AUTOSAR XML (schema 4-2-2)
standard types defined: UInt8, UInt16, uint8, uint16
package /SwcCELCmgr_pkg/SwcCELCmgr_swc
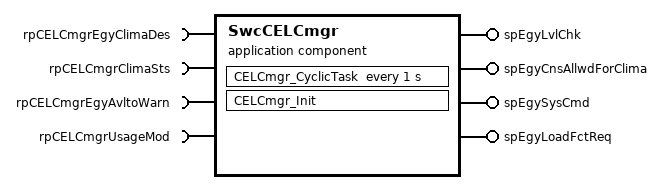
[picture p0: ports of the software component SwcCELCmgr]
  application sw component type SwcCELCmgr
    4 x require port:
      rpCELCmgrEgyClimaDes: nonqueued-receiver-com-spec{data-element=EgyClimaDes, alive-timeout=60, init-value=constant-reference={short-label=DefaultInitValue_UInt16, constant=DefaultInitValue_UInt16}}, required-interface=rpCELCmgrEgyClimaDes
      rpCELCmgrClimaSts: nonqueued-receiver-com-spec{data-element=ClimaSts, alive-timeout=60, init-value=constant-reference={short-label=DefaultInitValue_UInt8, constant=DefaultInitValue_UInt8}}, required-interface=rpCELCmgrClimaSts
      rpCELCmgrEgyAvltoWarn: nonqueued-receiver-com-spec{data-element=EgyAvltoWarn, alive-timeout=60, init-value=constant-reference={short-label=DefaultInitValue_UInt16, constant=DefaultInitValue_UInt16}}, required-interface=rpCELCmgrEgyAvltoWarn
      rpCELCmgrUsageMod: nonqueued-receiver-com-spec{data-element=UsageMod, alive-timeout=60, init-value=constant-reference={short-label=DefaultInitValue_UInt8, constant=DefaultInitValue_UInt8}}, required-interface=rpCELCmgrUsageMod
    4 x provide port:
      spEgyLvlChk: nonqueued-sender-com-spec{data-element=EgyLvlChk, init-value=constant-reference={short-label=DefaultInitValue_UInt8, constant=DefaultInitValue_UInt8}}, provided-interface=spEgyLvlChk
      spEgyCnsAllwdForClima: nonqueued-sender-com-spec{data-element=EgyCnsAllwdForClima, init-value=constant-reference={short-label=DefaultInitValue_UInt16, constant=DefaultInitValue_UInt16}}, provided-interface=spEgyCnsAllwdForClima
      spEgySysCmd: nonqueued-sender-com-spec{data-element=EgySysCmd, init-value=constant-reference={short-label=DefaultInitValue_UInt8, constant=DefaultInitValue_UInt8}}, provided-interface=spEgySysCmd
      spEgyLoadFctReq: nonqueued-sender-com-spec{data-element=EgyLoadFctReq, init-value=constant-reference={short-label=DefaultInitValue_UInt8, constant=DefaultInitValue_UInt8}}, provided-interface=spEgyLoadFctReq
    behavior SwcCELCmgr: handle-termination-and-restart=NO-SUPPORT
      constant-memorys:
        4 x parameter data prototype, all with category=VALUE, sw-calibration-access=READ-WRITE:
          CELCmgr_TEgyChkTime_5min: type=UInt16, init-value=constant-reference={short-label=CELCmgr_TEgyChkTime_5min, constant=CELCmgr_TEgyChkTime_5min}
          CELCmgr_EgyClimaAllwdFac: type=UInt8, init-value=constant-reference={short-label=CELCmgr_EgyClimaAllwdFac, constant=CELCmgr_EgyClimaAllwdFac}
          CELCmgr_EgyCnsAllwdForClimaMax: type=UInt8, init-value=constant-reference={short-label=CELCmgr_EgyCnsAllwdForClimaMax, constant=CELCmgr_EgyCnsAllwdForClimaMax}
          CELCmgr_TclimaMax: type=UInt8, init-value=constant-reference={short-label=CELCmgr_TclimaMax, constant=CELCmgr_TclimaMax}
      timing event Event_Runnable_Step: start-on-event=CELCmgr_CyclicTask, period=1
      init event Event: start-on-event=CELCmgr_Init
      runnable CELCmgr_Init
      runnable CELCmgr_CyclicTask
        data-read-access:
          4 x access:
            IN_rpCELCmgrClimaSts_ClimaSts: accessed-variable=rpCELCmgrClimaSts.ClimaSts
            IN_rpCELCmgrEgyAvltoWarn_EgyAvltoWarn: accessed-variable=rpCELCmgrEgyAvltoWarn.EgyAvltoWarn
            IN_rpCELCmgrEgyClimaDes_EgyClimaDes: accessed-variable=rpCELCmgrEgyClimaDes.EgyClimaDes
            IN_rpCELCmgrUsageMod_UsageMod: accessed-variable=rpCELCmgrUsageMod.UsageMod
        data-write-access:
          4 x access:
            OUT_spEgyLvlChk_EgyLvlChk: accessed-variable=spEgyLvlChk.EgyLvlChk
            OUT_spEgyCnsAllwdForClima_EgyCnsAllwdForClima: accessed-variable=spEgyCnsAllwdForClima.EgyCnsAllwdForClima
            OUT_spEgySysCmd_EgySysCmd: accessed-variable=spEgySysCmd.EgySysCmd
            OUT_spEgyLoadFctReq_EgyLoadFctReq: accessed-variable=spEgyLoadFctReq.EgyLoadFctReq
  8 x sender receiver interface:
    rpCELCmgrEgyClimaDes
      data EgyClimaDes: category=VALUE, type=UInt16
    rpCELCmgrClimaSts
      data ClimaSts: category=VALUE, type=UInt8
    rpCELCmgrEgyAvltoWarn
      data EgyAvltoWarn: category=VALUE, type=UInt16
    rpCELCmgrUsageMod
      data UsageMod: category=VALUE, type=UInt8
    spEgyLvlChk
      data EgyLvlChk: category=VALUE, type=UInt8
    spEgyCnsAllwdForClima
      data EgyCnsAllwdForClima: category=VALUE, type=UInt16
    spEgySysCmd
      data EgySysCmd: category=VALUE, type=UInt8
    spEgyLoadFctReq
      data EgyLoadFctReq: category=VALUE, type=UInt8
package /SwcCELCmgr_pkg/SwcCELCmgr_swc/Ground
  7 x constant specification:
    CELCmgr_EgyClimaAllwdFac: value-spec=CELCmgr_EgyClimaAllwdFac:80
    CELCmgr_Tclima: value-spec=CELCmgr_Tclima:60
    CELCmgr_TEgyChkTime_5min: value-spec=CELCmgr_TEgyChkTime_5min:30000
    CELCmgr_TclimaMax: value-spec=CELCmgr_TclimaMax:12
    DefaultInitValue_UInt8: value-spec=0
    DefaultInitValue_UInt16: value-spec=0
    CELCmgr_EgyCnsAllwdForClimaMax: value-spec=CELCmgr_EgyCnsAllwdForClimaMax:127
package /SwcCELCmgr_pkg/SwcCELCmgr_imp
  swc implementation SwcCELCmgr: programming-language=C, sw-version=1.232.1, used-code-generator=Embedded Coder 6.13 (R2017b) 24-Jul-2017, vendor-id=0, behavior=SwcCELCmgr
    code-descriptors:
      code Code
        artifact-descriptors:
          short-label=SwcCELCmgr_c, category=SWSRC
          short-label=ChartInfoStruct_h, category=SWHDR
          short-label=DebuggerRuntimeInterface_h, category=SWHDR
          short-label=MatlabDataArray_hpp, category=SWHDR
          short-label=MatlabEngine_hpp, category=SWHDR
          short-label=MessageServiceLayer_h, category=SWHDR
          short-label=SwcCELCmgr_h, category=SWHDR
          short-label=SwcCELCmgr_private_h, category=SWHDR
          short-label=SwcCELCmgr_types_h, category=SWHDR
          short-label=bio_sig_h, category=SWHDR
          short-label=blas_h, category=SWHDR
          short-label=blascompat32_h, category=SWHDR
          short-label=cg_matrx_h, category=SWHDR
          short-label=cg_sfun_h, category=SWHDR
          short-label=cgxert_h, category=SWHDR
          short-label=covrt_h, category=SWHDR
          short-label=cvstCG_ComputeMetric_h, category=SWHDR
          short-label=cvstCG_foregroundDetector_h, category=SWHDR
          short-label=cvstCG_ocrutils_h, category=SWHDR
          short-label=dt_info_h, category=SWHDR
          short-label=emlrt_h, category=SWHDR
          short-label=engine_h, category=SWHDR
          short-label=ext_share_h, category=SWHDR
          short-label=ext_svr_h, category=SWHDR
          short-label=ext_svr_transport_h, category=SWHDR
          short-label=ext_test_h, category=SWHDR
          short-label=ext_types_h, category=SWHDR
          short-label=ext_work_h, category=SWHDR
          short-label=fintrf_h, category=SWHDR
          short-label=fixedpoint_h, category=SWHDR
          short-label=fixpoint_spec_h, category=SWHDR
          short-label=io64_h, category=SWHDR
          short-label=lapack_h, category=SWHDR
          short-label=lapacke_h, category=SWHDR
          short-label=lapacke_config_h, category=SWHDR
          short-label=libmwboxfilter_h, category=SWHDR
          short-label=libmwboxfilter3_h, category=SWHDR
          short-label=libmwbwdistEDT_h, category=SWHDR
          short-label=libmwbwdistEDTFT_h, category=SWHDR
          short-label=libmwbwdistEDTFT_tbb_h, category=SWHDR
          short-label=libmwbwdistEDT_tbb_h, category=SWHDR
          short-label=libmwbwlookup_h, category=SWHDR
          short-label=libmwbwlookup_tbb_h, category=SWHDR
          short-label=libmwbwpackc_h, category=SWHDR
          short-label=libmwbwpackctbb_h, category=SWHDR
          short-label=libmwbwunpackc_h, category=SWHDR
          short-label=libmwbwunpackctbb_h, category=SWHDR
          short-label=libmwcannythresholding_tbb_h, category=SWHDR
          short-label=libmwddist_h, category=SWHDR
          short-label=libmwedgesobelprewitt_tbb_h, category=SWHDR
          short-label=libmwedgethinning_tbb_h, category=SWHDR
          short-label=libmwgetnumcores_h, category=SWHDR
          short-label=libmwgrayto16_h, category=SWHDR
          short-label=libmwgrayto8_h, category=SWHDR
          short-label=libmwgrayxform_h, category=SWHDR
          short-label=libmwgrayxform_tbb_h, category=SWHDR
          short-label=libmwimfilter_h, category=SWHDR
          short-label=libmwimlincomb_h, category=SWHDR
          short-label=libmwimlincomb_tbb_h, category=SWHDR
          short-label=libmwimreconstruct_h, category=SWHDR
          short-label=libmwimregionalmax_h, category=SWHDR
          short-label=libmwint16touint16_h, category=SWHDR
          short-label=libmwint32touint32_h, category=SWHDR
          short-label=libmwint8touint8_h, category=SWHDR
          short-label=libmwintlut_h, category=SWHDR
          short-label=libmwintluttbb_h, category=SWHDR
          short-label=libmwippfilter_h, category=SWHDR
          short-label=libmwippgeotrans_h, category=SWHDR
          short-label=libmwippmedianfilter_h, category=SWHDR
          short-label=libmwippreconstruct_h, category=SWHDR
          short-label=libmwjpegreader_h, category=SWHDR
          short-label=libmwmorphop_binary_h, category=SWHDR
          short-label=libmwmorphop_binary_tbb_h, category=SWHDR
          short-label=libmwmorphop_flat_h, category=SWHDR
          short-label=libmwmorphop_flat_tbb_h, category=SWHDR
          short-label=libmwmorphop_nonflat_h, category=SWHDR
          short-label=libmwmorphop_nonflat_tbb_h, category=SWHDR
          short-label=libmwmorphop_ocv_h, category=SWHDR
          short-label=libmwmorphop_packed_h, category=SWHDR
          short-label=libmwordfilt2_h, category=SWHDR
          short-label=libmwremap_h, category=SWHDR
          short-label=libmwremaptbb_h, category=SWHDR
          short-label=libmwrgb2gray_tbb_h, category=SWHDR
          short-label=libmwrgb2hsv_tbb_h, category=SWHDR
          short-label=libmwtbbhist_h, category=SWHDR
          short-label=libmwuint16toint16_h, category=SWHDR
          short-label=mat_h, category=SWHDR
          short-label=matrix_h, category=SWHDR
          short-label=mclbase_h, category=SWHDR
          short-label=mclcom_h, category=SWHDR
          short-label=mclcomclass_h, category=SWHDR
          short-label=mclcommain_h, category=SWHDR
          short-label=mclcppclass_h, category=SWHDR
          short-label=mclmcr_h, category=SWHDR
          short-label=mclmcrrt_h, category=SWHDR
          short-label=mclxlmain_h, category=SWHDR
          short-label=mcr_h, category=SWHDR
          short-label=mdl_info_h, category=SWHDR
          short-label=mem_mgr_h, category=SWHDR
          short-label=mex_h, category=SWHDR
          short-label=mwmathutil_h, category=SWHDR
          short-label=mwservices_h, category=SWHDR
          short-label=odesup_h, category=SWHDR
          short-label=opencvgpumex_hpp, category=SWHDR
          short-label=opencvmex_hpp, category=SWHDR
          short-label=polygonBoolean_h, category=SWHDR
          short-label=pt_info_h, category=SWHDR
          short-label=rt_logging_h, category=SWHDR
          short-label=rt_logging_mmi_h, category=SWHDR
          short-label=rt_math_h, category=SWHDR
          short-label=rt_matrx_h, category=SWHDR
          short-label=rt_mxclassid_h, category=SWHDR
          short-label=rt_sim_h, category=SWHDR
          short-label=rtiostream_h, category=SWHDR
          short-label=rtmcmacros_h, category=SWHDR
          short-label=rtmmacros_h, category=SWHDR
          short-label=rtsplntypes_h, category=SWHDR
          short-label=rtw_capi_h, category=SWHDR
          short-label=rtw_capi_examples_h, category=SWHDR
          short-label=rtw_continuous_h, category=SWHDR
          short-label=rtw_extmode_h, category=SWHDR
          short-label=rtw_linux_h, category=SWHDR
          short-label=rtw_linux_mac_h, category=SWHDR
          short-label=rtw_matlogging_h, category=SWHDR
          short-label=rtw_modelmap_h, category=SWHDR
          short-label=rtw_modelmap_logging_h, category=SWHDR
          short-label=rtw_msvc_lshift_h, category=SWHDR
          short-label=rtw_solver_h, category=SWHDR
          short-label=rtw_windows_h, category=SWHDR
          short-label=rtw_xpc_h, category=SWHDR
          short-label=rtwtypes_h, category=SWHDR
          short-label=sf_runtime_errors_h, category=SWHDR
          short-label=sf_runtime_spec_h, category=SWHDR
          short-label=sf_runtime_types_h, category=SWHDR
          short-label=sf_test_language_h, category=SWHDR
          short-label=sfc_api_h, category=SWHDR
          short-label=sfc_messages_h, category=SWHDR
          short-label=sfc_mex_h, category=SWHDR
          short-label=sfc_sdi_h, category=SWHDR
          short-label=sfc_sf_h, category=SWHDR
          short-label=sfcdebug_h, category=SWHDR
          short-label=sfcn_bridge_h, category=SWHDR
          short-label=sfcn_loader_c_api_h, category=SWHDR
          short-label=sfun_rtwcg_hpp, category=SWHDR
          short-label=sigmapdef_sfcn_h, category=SWHDR
          short-label=sigregdef_h, category=SWHDR
          short-label=sigstream_rtw_h, category=SWHDR
          short-label=simlogCIntrf_h, category=SWHDR
          short-label=simstruc_h, category=SWHDR
          short-label=simstruc_types_h, category=SWHDR
          short-label=simulink_h, category=SWHDR
          short-label=simulink2_h, category=SWHDR
          short-label=simulink_solver_api_h, category=SWHDR
          short-label=slTestResult_h, category=SWHDR
          short-label=slTestTypes_h, category=SWHDR
          short-label=sl_common_types_def_h, category=SWHDR
          short-label=sl_datatype_access_h, category=SWHDR
          short-label=sl_fileio_rtw_h, category=SWHDR
          short-label=sl_fixpt_h, category=SWHDR
          short-label=sl_prodhwdevicetype_h, category=SWHDR
          short-label=sl_report_types_h, category=SWHDR
          short-label=sl_sample_time_defs_h, category=SWHDR
          short-label=sl_sfcn_st_api_h, category=SWHDR
          short-label=sl_solver_rtw_h, category=SWHDR
          short-label=sl_types_def_h, category=SWHDR
          short-label=slexec_block_runtime_service_h, category=SWHDR
          short-label=slexec_parallel_h, category=SWHDR
          short-label=slexec_simbridge_h, category=SWHDR
          short-label=slexec_simstruct_bridge_h, category=SWHDR
          short-label=slexec_vm_lookup_functions_h, category=SWHDR
          short-label=slexec_vm_rt_functions_h, category=SWHDR
          short-label=slexec_vm_simstruct_bridge_h, category=SWHDR
          short-label=slexec_vm_zc_functions_h, category=SWHDR
          short-label=slsv_diagnostic_codegen_c_api_h, category=SWHDR
          short-label=slsv_diagnostic_logger_type_h, category=SWHDR
          short-label=slsv_mexhelper_h, category=SWHDR
          short-label=solver_zc_h, category=SWHDR
          short-label=sysran_types_h, category=SWHDR
          short-label=tmwtypes_h, category=SWHDR
          short-label=updown_h, category=SWHDR
          short-label=updown_util_h, category=SWHDR
          short-label=upsup_public_h, category=SWHDR
          short-label=utils_h, category=SWHDR
    resource consumption RsrcCons_SwcCELCmgr
